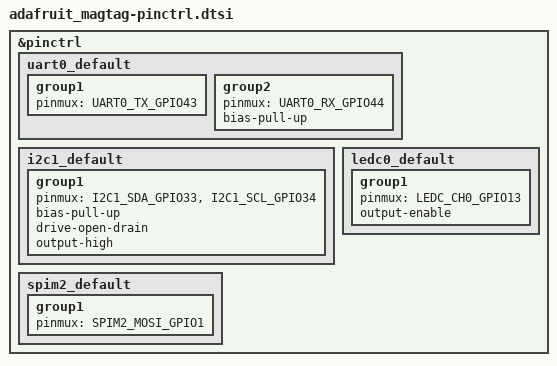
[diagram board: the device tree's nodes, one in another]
/*
 * Copyright (c) 2023 Golioth, Inc.
 *
 * SPDX-License-Identifier: Apache-2.0
 */

#include <zephyr/dt-bindings/pinctrl/esp-pinctrl-common.h>
#include <dt-bindings/pinctrl/esp32s2-pinctrl.h>
#include <zephyr/dt-bindings/pinctrl/esp32s2-gpio-sigmap.h>

&pinctrl {

    uart0_default: uart0_default {
        group1 {
            pinmux = <UART0_TX_GPIO43>;
        };
        group2 {
            pinmux = <UART0_RX_GPIO44>;
            bias-pull-up;
        };
    };

    i2c1_default: i2c1_default {
        group1 {
            pinmux = <I2C1_SDA_GPIO33>, <I2C1_SCL_GPIO34>;
            bias-pull-up;
            drive-open-drain;
            output-high;
        };
    };

    spim2_default: spim2_default {
        group1 {
            pinmux = <SPIM2_MOSI_GPIO1>;
        };
        /delete-node/ group2;
    };

    ledc0_default: ledc0_default {
        group1 {
            pinmux = <LEDC_CH0_GPIO13>;
            output-enable;
        };
    };

};
